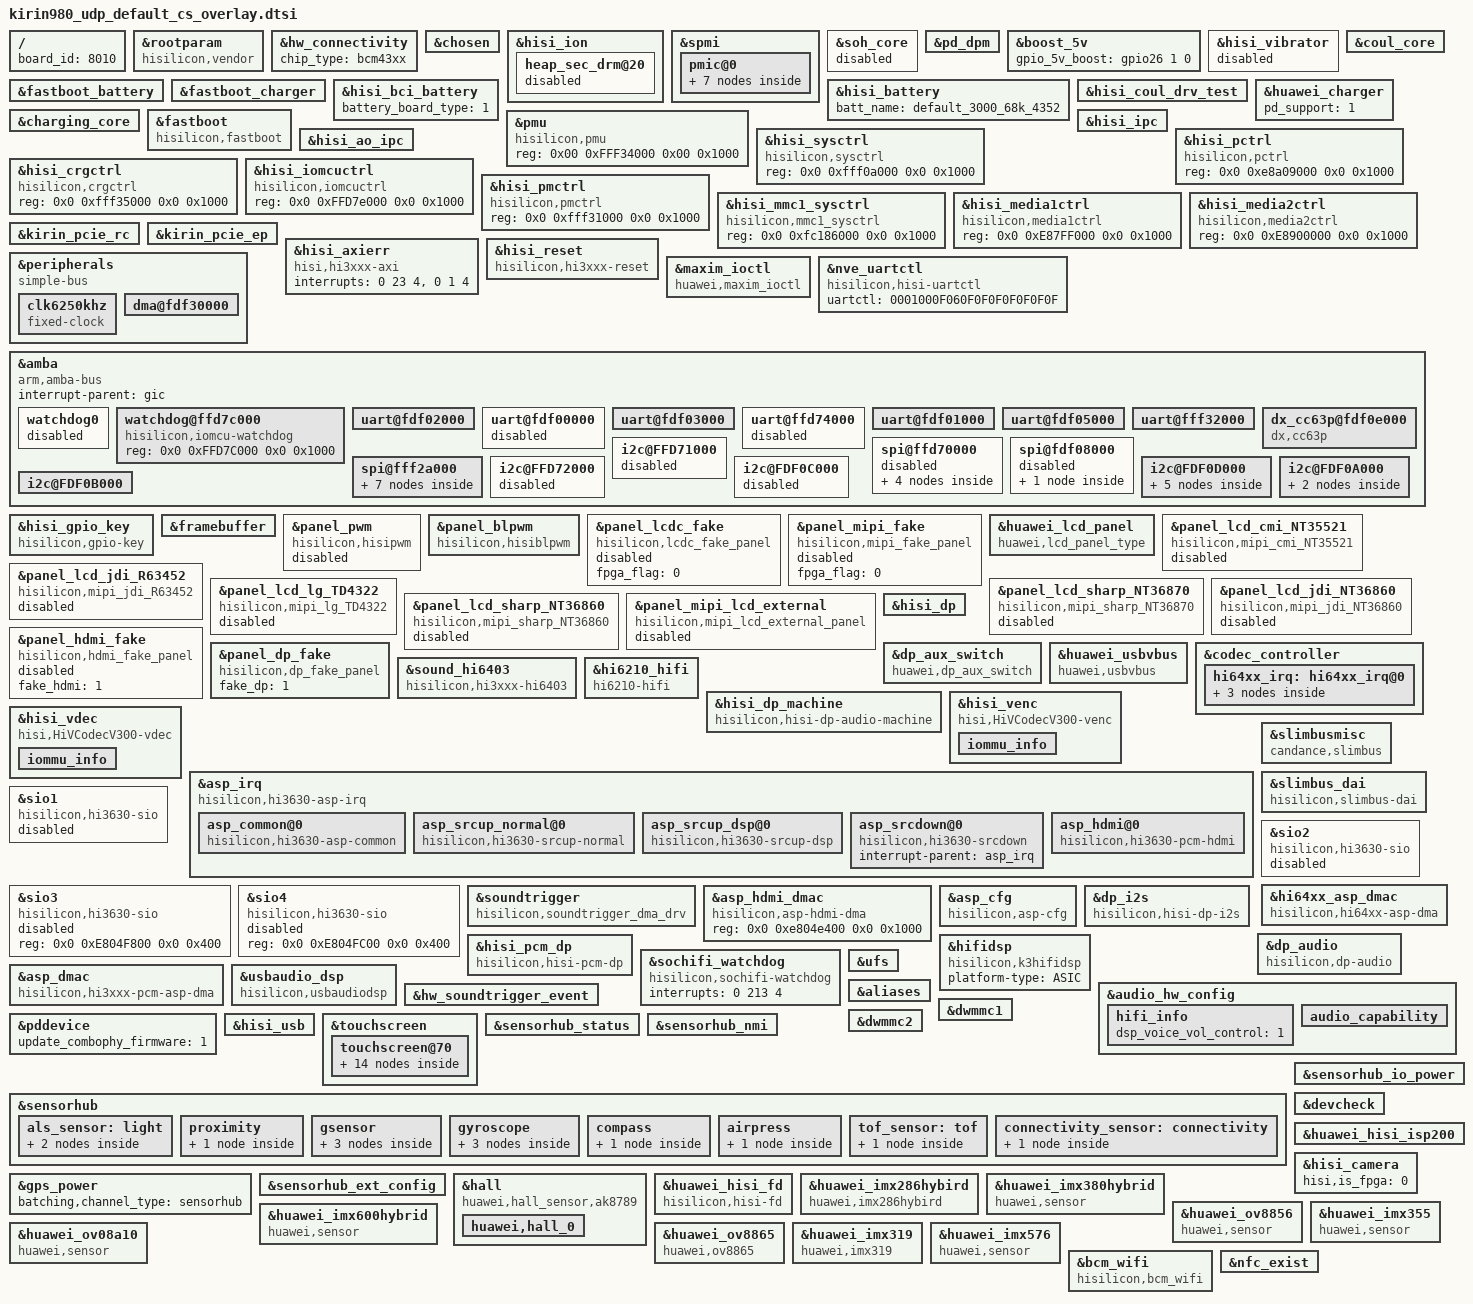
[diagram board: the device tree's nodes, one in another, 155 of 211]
/**
 * Copyright (C) 2014 Hisilicon Ltd.
 *
 *  This program is free software; you can redistribute it and/or modify
 *  it under the terms of the GNU General Public License version 2 as
 *  publishhed by the Free Software Foundation.
 */

/include/ "kirin980_udp_default_cs_pin.dtsi"
/include/ "kirin980_udp_default_cs_modem_pin.dtsi"
/include/ "kirin980_udp_default_cs_hi6402_pin.dtsi"
/include/ "default_3000_68k_4352.dtsi"

/ {
    board_id = <8010>;
};

	&rootparam{
		compatible = "hisilicon,vendor";
		hisi,boardid = <8 0 1 0>;
		hisi,boardname = "kirin980_udp_default_cs";
		hisi,modem_id = <0x37F5FC10>;
		hisi,product_id = <0x37F5FC10>;
	};
	&hw_connectivity {
		/*huawei configuration*/
		chip_type = "bcm43xx";
		status = "ok";
	};
	&chosen {};

	&hisi_ion {
		heap_sec_drm@20 {
			status = "disabled";
		};
	};
	&spmi {
		pmic@0 {
			gpios = <&gpio28 0 0>;
			hisilicon,pmic_fpga_flag=<0>;
				pmic_led@a0 {
					status = "ok";
				};
				pmic_rtc@a0 {
					status = "ok";
				};
				ponkey@b1{
		           		status = "ok";
				};
				pmic_mntn@a0 {
					status = "ok";
				};
				hi6421v700_coul@1 {
					status = "ok";
                                };
				hisi_soh_pmic@1 {
					status = "disabled";
				};
				pmic_vibrator {
					status = "ok";
					hisi_pmic_vibrator,max-timeout-ms = <10000>;
					hisi_pmic_vibrator,label = "vibrator";
					vibrator-reg-on = <0xA000>;
					vibrator-reg-off = <0xA001>;
					vibrator-voltage = <1400>;
					vibrator-boost-power = <0>; // 0: not used 5V, 1 used
					haptics-cfg =
						<0x00 0x00 0x08 0x0f 0x10 0x00 0x18 0x0f 0x1f 0x00 0x26 0x0f 0x2d 0x00 0x32 0x0f 0x37 0x00 0x3b 0x0f 0x3d 0xc0 0x3f 0x0d 0x40 0x00 0x40 0x00 0x40 0x00 0x40 0x00 0x40 0x00 0x40 0x00 0x40 0x00 0x40 0x00>,//6 cycle
						<0x00 0x00 0x08 0x0f 0x10 0x00 0x18 0x0f 0x1f 0x00 0x26 0x0f 0x2d 0x00 0x32 0x0f 0x37 0x00 0x3b 0x0f 0x3d 0x00 0x3f 0x0f 0x40 0x00 0x40 0x0f 0x40 0xf0 0x40 0x07 0x40 0x00 0x40 0x00 0x40 0x00 0x40 0x00>,//8 cycle
						<0x00 0x00 0x08 0x0f 0x10 0x00 0x18 0x0f 0x1f 0x00 0x26 0x0f 0x2d 0x00 0x32 0x0f 0x37 0x00 0x3b 0x0f 0x3d 0x00 0x3f 0x0f 0x40 0x00 0x40 0x0f 0x40 0x00 0x40 0x0f 0x40 0x00 0x40 0x0f 0x40 0xf0 0x40 0x07>,//10 cycle
						<0x00 0x40 0x08 0x0b 0x10 0x40 0x18 0x0b 0x1f 0x40 0x26 0x0b 0x2d 0x40 0x32 0x0b 0x37 0x40 0x3b 0x0b 0x3d 0x50 0x3f 0x0a 0x40 0x00 0x40 0x00 0x40 0x00 0x40 0x00 0x40 0x00 0x40 0x00 0x40 0x00 0x40 0x00>,//%75 6 cycle
						<0x00 0x80 0x08 0x07 0x10 0x80 0x18 0x07 0x1f 0x80 0x26 0x07 0x2d 0x80 0x32 0x07 0x37 0x80 0x3b 0x07 0x3d 0x40 0x3f 0x06 0x40 0x00 0x40 0x00 0x40 0x00 0x40 0x00 0x40 0x00 0x40 0x00 0x40 0x00 0x40 0x00>;//%50 6 cycle
				};
		};
	};
	&soh_core {
		status = "disabled";
	};
	&pd_dpm {
		uart_use_sbu = <1>;
		uart_rx_gpio = <&gpio4 5 0>;
		uart_tx_gpio = <&gpio4 6 0>;
		status = "ok";
	};

	&boost_5v {
		gpio_5v_boost = <&gpio26 1 0>;
		status = "ok";
	};

	&hisi_vibrator {
		status = "disabled";
	};

	&fastboot_battery {
		status = "ok";
	};
	&fastboot_charger {
		hw_charger_type = <4>;
		chip_i2c_num = <6>;
		status = "ok";
	};
	&hisi_battery {
		batt_name = <&default_3000_68k_4352>;
		status = "ok";
	};
	&hisi_bci_battery {
		battery_board_type = <1>; /*0:sft 1:udp 2:asic*/
		status = "ok";
	};
	&coul_core {
		adc_batt_id = <11>;
		adc_batt_temp = <10>;
		r_coul_mohm = <5>;
		status = "ok";
	};
	&hisi_coul_drv_test {
		status = "ok";
	};
	&huawei_charger {
		pd_support = <1>;
		status = "ok";
	};
	&charging_core {
		status = "ok";
	};

	&fastboot {
		compatible = "hisilicon,fastboot";
		i2c3-pin = <0>;
		gpio-keyup = <213>;
		gpio-keydown = <210>;
		uart-board-type = <1>;
		/*UDP_TYPE 0,PRODUCT 1,FPGA 2,EMU 3*/
		lpm3-board-type = <0>;
		jtagtosd-board-type = <2>;
		motor-vib_type = <0>;

		i2c-select = <1>;
		i2c-sel0-gpio = <164>;
		i2c-sel1-gpio = <165>;
		i2c-sel0-val = <0>;
		i2c-sel1-val = <0>;
	};

	&pmu {
		compatible = "hisilicon,pmu";
		reg = <0x00 0xFFF34000 0x00 0x1000>;
		status = "ok";
	};

	&hisi_ipc {

	};
	&hisi_ao_ipc {

	};

        &hisi_sysctrl {
                compatible = "hisilicon,sysctrl";
                reg = <0x0 0xfff0a000 0x0 0x1000>;
                status = "ok";
        };

        &hisi_pctrl {
                compatible = "hisilicon,pctrl";
                reg = <0x0 0xe8a09000 0x0 0x1000>;
                status = "ok";
        };

        &hisi_crgctrl {
                compatible = "hisilicon,crgctrl";
                reg = <0x0 0xfff35000 0x0 0x1000>;
                status = "ok";
        };

	&hisi_iomcuctrl {
                compatible = "hisilicon,iomcuctrl";
                reg = <0x0 0xFFD7e000 0x0 0x1000>;
                status = "ok";
        };

        &hisi_pmctrl {
                compatible = "hisilicon,pmctrl";
                reg = <0x0 0xfff31000 0x0 0x1000>;
                status = "ok";
        };

        &hisi_mmc1_sysctrl {
                compatible = "hisilicon,mmc1_sysctrl";
                reg = <0x0 0xfc186000 0x0 0x1000>;
                status = "ok";
        };

        &hisi_media1ctrl {
                compatible = "hisilicon,media1ctrl";
                reg = <0x0 0xE87FF000 0x0 0x1000>;
                status = "ok";
        };

        &hisi_media2ctrl {
                compatible = "hisilicon,media2ctrl";
                reg = <0x0 0xE8900000 0x0 0x1000>;
                status = "ok";
        };
	&kirin_pcie_rc {
		/* WL_EN GPIO, for Hardware and SoC dependability test */
		wl_power = <200>;

		/* LTR latency param comes from EP: BCM43596 -- 0x10031003 */
		ep_ltr_latency = <0x10031003>;

		/* T-poweron comes from EP: BCM43596 -- 0x10031003 */
		ep_l1ss_ctrl2 = <0x61>;

		/* the lower_16(l1ss_ctrl1) 0x370F needed by RC and must be set; the upper_16 comes from EP*/
		l1ss_ctrl1 = <0x4004370F>;

		/* Delay time come from BCM43596 powerup sequence */
		t_ref2perst = <21000 23000>;
		t_perst2access = <7000 8000>;
		t_perst2rst = <10000 11000>;
	};


	&kirin_pcie_ep {
	};

	&hisi_axierr {
	        compatible = "hisi,hi3xxx-axi";
	        interrupts = <0 23 4>, <0 1 4>;
	        status = "ok";
        };

    &hisi_reset {
            compatible = "hisilicon,hi3xxx-reset";
            status = "ok";
        };

	&peripherals {
		compatible = "simple-bus";
		#address-cells = <1>;
		#size-cells = <1>;
		ranges = <0x0 0x00000000 0x0 0xffffffff>;

		clk6250khz {
			compatible = "fixed-clock";
			#clock-cells = <0>;
			clock-frequency = <6297600>;
			clock-output-names = "clk6250khz";
		};
/*
		clk4800khz {
			compatible = "fixed-clock";
			#clock-cells = <0>;
			clock-frequency = <32768>;
			clock-output-names = "clk4800khz";
		};
*/

		dma@fdf30000 {
			status = "ok";
		};
	};

	&maxim_ioctl {
		compatible = "huawei,maxim_ioctl";
		status = "ok";
	};

	&nve_uartctl {
		compatible = "hisilicon,hisi-uartctl";
		uartctl = "0001000F060F0F0F0F0F0F0F";
	};
	&amba {
		#address-cells = <2>;
		#size-cells = <2>;
		compatible = "arm,amba-bus";
		interrupt-parent = <&gic>;
		ranges;

		/*rtc0: rtc@FFF04000 {
				compatible = "arm,rtc-pl031", "arm,primecell";
				reg = <0xfff04000 0x1000>;
				interrupts = <0 46 0x4>;
				clocks = <&pclk>;
				clock-names = "apb_pclk";
				status = "ok";
		};*/

		/* rtc@FFF05000 {
				compatible = "arm,rtc-pl031", "arm,primecell";
				reg = <0xfff05000 0x1000>;
				interrupts = <0 47 0x4>;
				clocks = <&pclk>;
				clock-names = "apb_pclk";
				status = "ok";
		};*/

		watchdog0 {
			status = "disabled";
		};

                watchdog@ffd7c000{
                        compatible = "hisilicon,iomcu-watchdog";
                        reg = <0x0 0xFFD7C000 0x0 0x1000>;
                        status = "ok";
                };

		/*wdt1@e8a07000 {
			compatible = "arm,sp805", "arm,primecell";
			reg = <0x0 0xe8a07000 0x0 0x1000>;
			interrupts = <0 45 4>;
			clocks = <&pclk_gate_wd0 &pclk>;
			clock-names = "pclk_wd0", "apb_pclk";
		};*/

		uart@fdf02000 {
			status = "ok";
		};

		uart@fdf00000 {
			status = "disabled";
		};

		uart@fdf03000 {
			status = "ok";
		};

		uart@ffd74000 {
			status = "disabled";
		};

		uart@fdf01000 {
			status = "ok";
		};

		uart@fdf05000 {
			status = "ok";
		};

		uart@fff32000 {
			status = "ok";
		};

		dx_cc63p@fdf0e000 {
			compatible = "dx,cc63p";
			reg = <0x0 0xfdf0e000 0x0 0x1000>;
			interrupt-parent = <&gic>;
			interrupts = <0 135 4>;
			status = "ok";
		};

		spi@ffd70000 {
			status = "disabled";
			spi_dev0@0 {
					compatible = "spi_dev0";
					spi-max-frequency = <100000>;
					reg = <0>;
					pl022,com-mode = <0>;
					pl022,interface = <0>;
					pl022,rx-level-trig = <3>;
					pl022,tx-level-trig = <3>;
					pl022,ctrl-len = <7>;
					pl022,wait-state = <0>;
					pl022,duplex = <0>;
					pl022,slave-tx-disable = <0>;
			};

			spi_dev1@1 {
					compatible = "spi_dev1";
					spi-max-frequency = <13000000>;
					reg = <1>;
					pl022,com-mode = <1>;
					pl022,interface = <0>;
					pl022,rx-level-trig = <3>;
					pl022,tx-level-trig = <3>;
					pl022,ctrl-len = <7>;
					pl022,wait-state = <0>;
					pl022,duplex = <0>;
					pl022,slave-tx-disable = <0>;
			};

			spi_dev2@2 {
					compatible = "spi_dev2";
					spi-max-frequency = <13000000>;
					reg = <2>;
					pl022,com-mode = <2>;
					pl022,interface = <0>;
					pl022,rx-level-trig = <3>;
					pl022,tx-level-trig = <3>;
					pl022,ctrl-len = <7>;
					pl022,wait-state = <0>;
					pl022,duplex = <0>;
					pl022,slave-tx-disable = <0>;
			};

			spi_dev3@3 {
					compatible = "spi_dev3";
					spi-max-frequency = <13000000>;
					reg = <3>;
					pl022,com-mode = <0>;
					pl022,interface = <0>;
					pl022,rx-level-trig = <3>;
					pl022,tx-level-trig = <3>;
					pl022,ctrl-len = <7>;
					pl022,wait-state = <0>;
					pl022,duplex = <0>;
					pl022,slave-tx-disable = <0>;
			};
		};

		spi@fdf08000 {
			status = "disabled";
			spi_dev10@10 {
					compatible = "spi_dev10";
					spi-max-frequency = <100000>;
					reg = <0>;
					pl022,com-mode = <0>;
					pl022,interface = <0>;
					pl022,rx-level-trig = <3>;
					pl022,tx-level-trig = <3>;
					pl022,ctrl-len = <7>;
					pl022,wait-state = <0>;
					pl022,duplex = <0>;
					pl022,slave-tx-disable = <0>;
			};
		};

		spi@fff2a000 {
			status = "ok";
			huawei_thp@10 {
				compatible = "huawei,thp";
				spi-max-frequency = <10000000>;
				spi-bus-id = <3>;
				reg = <0>;
				kirin-udp;
				pl022,com-mode = <2>;
				pl022,interface = <0>;
				pl022,rx-level-trig = <3>;
				pl022,tx-level-trig = <3>;
				pl022,ctrl-len = <7>;
				pl022,wait-state = <0>;
				pl022,duplex = <0>;
				pl022,slave-tx-disable = <0>;
				irq_gpio = <&gpio26 4 0>;
				cs_gpio = <&gpio29 4 0>;
				rst_gpio = <&gpio1 7 0>;
				boot_reset_hi_delay_ms = <1>;
				boot_reset_low_delay_ms = <0>;
				boot_reset_after_delay_ms = <0>;
				resume_reset_after_delay_ms = <1>;
				suspend_reset_after_delay_ms = <0>;
				spi_sync_cs_hi_delay_ns = <200>;
				spi_sync_cs_low_delay_ns = <10>;
				thp_input_dev {
					compatible = "huawei,thp_input";
					abs_max_x = <1440>;
					abs_max_y = <2560>;
				};
				novatech {
					spi_sync_cs_hi_delay_ns = <200>;
					spi_sync_cs_low_delay_ns = <200>;
				};
				rohm-bu21150 {
					spi_sync_cs_hi_delay_ns = <200>;
					spi_sync_cs_low_delay_ns = <10>;
				};
			};

			spi_dev30@30 {
					compatible = "spi_dev30";
					spi-max-frequency = <13000000>;
					reg = <1>;
					pl022,com-mode = <0>;
					pl022,interface = <0>;
					pl022,rx-level-trig = <3>;
					pl022,tx-level-trig = <3>;
					pl022,ctrl-len = <7>;
					pl022,wait-state = <0>;
					pl022,duplex = <0>;
					pl022,slave-tx-disable = <0>;
			};

			spi_dev31@31 {
					compatible = "spi_dev31";
					spi-max-frequency = <13000000>;
					reg = <2>;
					pl022,com-mode = <1>;
					pl022,interface = <0>;
					pl022,rx-level-trig = <3>;
					pl022,tx-level-trig = <3>;
					pl022,ctrl-len = <7>;
					pl022,wait-state = <0>;
					pl022,duplex = <0>;
					pl022,slave-tx-disable = <0>;
			};

			spi_dev32@32 {
					compatible = "spi_dev32";
					spi-max-frequency = <13000000>;
					reg = <3>;
					pl022,com-mode = <2>;
					pl022,interface = <0>;
					pl022,rx-level-trig = <3>;
					pl022,tx-level-trig = <3>;
					pl022,ctrl-len = <7>;
					pl022,wait-state = <0>;
					pl022,duplex = <0>;
					pl022,slave-tx-disable = <0>;
			};

		};
		/* I2C0 ~ I2C4 */
		i2c@FFD71000 {
			status = "disabled";
		};

		i2c@FFD72000 {
			status = "disabled";
		};

		i2c@FDF0C000 {
			status = "disabled";
		};

		i2c@FDF0D000 {
			status = "ok";

			smartpa@31 {
				status = "ok";
				gain_incall = <0x16>;
				gain = <0x16>;
			};

			smartpa@34 {
				status = "ok";
				gain_incall = <0x16>;
				gain = <0x16>;
			};

			hisi,ncp6925@50{
				compatible = "hisi,ncp6925";
				reg = <0x50>;
				hisi,pmic_name = "ncp6925";
				hisi,pmic_index = <0>;
				hisi,slave_address = <0x50>;
				hisi,pmic-pin = <75 999 999>;
				hisi,pmic-voltage = <0x0 0x1 0x2 0x3 0x4 0x5 0x6>;
				hisi,pmic_ex_func_disable = <1>;
				status = "ok";
			};
            huawei,lm3646@67{
                compatible = "huawei,lm3646";
                reg = <0x67>;
                huawei,flash-name = "lm3646";
                huawei,flash-index = <0>;
                huawei,flash-type = <0>;
                huawei,slave-address = <0x67>;
                huawei,flash-ctrltype = <1>;
                huawei,need-wakelock = <0>;
                huawei,flash-chipid = <0x11>;
                huawei,flash_led_num = <336>;
                huawei,flash_led = <0x0 0x1 0x2 0x3 0x4 0x5 0x6 0x7 0x8 0x9 0xa>;
				huawei,flash-pin = <231 999 999>;
                huawei,torch_led_num = <336>;
                huawei,torch_led = <0x0 0x1 0x2 0x3 0x4 0x5 0x6 0x7>;
                huawei,led-type = <1>; /* 1, dual tempature; 0, dual white */
                huawei,flash-current = <0x7c 0x7f 0x0>;
                status = "ok";
            };

			nfc@28{
				status = "ok";
				reg = <0x28>;
				compatible = "hisilicon,pn547_nfc";
				nfc_on_type = "hi6421v700_pmic";
				nfc_brcm_conf_name = "libnfc-brcm.conf";
				nfc_nxp_name = "libnfc-nxp.conf";
				nfc_card_num = <0x2>;
				clk_status ="pmu_hi6421v700";
				pn547,dload = <&gpio31 2 0>;
				pn547,irq = <&gpio27 3 0>;
				pn547,ven = <>;
				pinctrl-1 = <&gpio250_pmx_idle &gpio219_pmx_idle>;
				pinctrl-0 = <&gpio250_pmx_func &gpio219_pmx_func>;
				pinctrl-names = "default","idle";
				clock-names = "clk_out0";
				clocks = <&clk_gate_out0>;
				nfc_chip_type = "pn553";
				nfc_single_channel = "true";
				nfc_ese_type = "hisee";
			};

		};

		i2c@FDF0A000 {
			status = "ok";

			hi6523_charger_i2c6@6B{
				status = "ok";
				gpio_int = <&gpio27 2 0>;
			};
			rt1711_kirin980_i2c6@4e {
				status = "ok";
				rt1711,irq_pin = <&gpio25 7 0>;
			};
		};

		i2c@FDF0B000 {
			status = "ok";
		};
	};
	/* end amba */

	&hisi_gpio_key {
		compatible = "hisilicon,gpio-key";
		pinctrl-names = "default", "idle";
		pinctrl-0 = <&gpio213_cfg_func &gpio210_cfg_func>;
		pinctrl-1 = <&gpio213_cfg_idle &gpio210_cfg_idle>;
		gpio-keyup,gpio-irq = <&gpio26 5 0>;
		gpio-keydown,gpio-irq = <&gpio26 2 0>;
		status = "ok";
	};

	/* display start */
	&framebuffer {
		fpga_flag = <0>;
		//FB_ACCEL_KIRIN980
		dss_version_tag = <0x100>;
	};

	&panel_pwm {
		#address-cells = <2>;
		#size-cells = <2>;
		compatible = "hisilicon,hisipwm";
		reg = <0 0xE8A04000 0 0x1000>;
		clocks = <&clk_gate_pwm>;
		clock-names = "clk_pwm";
		//pinctrl-names = "default","idle";
		//pinctrl-0 = <&gpio182_pmx_func &gpio182_cfg_func>;
		//pinctrl-1 = <&gpio182_pmx_idle &gpio182_cfg_idle>;
		fpga_flag = <0>;
		status = "disabled";
	};

	&panel_blpwm {
		#address-cells = <2>;
		#size-cells = <2>;
		compatible = "hisilicon,hisiblpwm";
		reg = <0 0xFFD75000 0 0x1000>;
		clocks = <&clk_gate_blpwm>;
		clock-names = "clk_blpwm";
		pinctrl-names = "default","idle";
		pinctrl-0 = <&gpio185_pmx_func &gpio186_pmx_func &gpio185_cfg_func &gpio186_cfg_func>;
		pinctrl-1 = <&gpio185_pmx_idle &gpio186_pmx_idle &gpio185_cfg_idle &gpio186_cfg_idle>;
		fpga_flag = <0>;
		status = "ok";
	};

	&panel_lcdc_fake {
		#address-cells = <2>;
		#size-cells = <2>;
		compatible = "hisilicon,lcdc_fake_panel";
		fpga_flag = <0>;
		status = "disabled";
	};

	&panel_mipi_fake {
		#address-cells = <2>;
		#size-cells = <2>;
		compatible = "hisilicon,mipi_fake_panel";
		fpga_flag = <0>;
		status = "disabled";
	};

	&huawei_lcd_panel {
		compatible = "huawei,lcd_panel_type";
		detect_type = <0>;		/*0:DETECT_GPIOID  1:DETECT_CHIPID  2:DETECT_LCD_TYPE */
		gpio_id = <16 9>;
		gpio_cfg_addr = <0xE896CF24 0xE896CF08>;
		support_lcd_type = "JDI_R63452_LCD", "LG_TD4322_LCD", "SHARP_NT36870_LCD";
		lcd_id_match_tab = <0 4 2>;
	};

	&panel_lcd_cmi_NT35521 {
		#address-cells = <2>;
		#size-cells = <2>;
		compatible = "hisilicon,mipi_cmi_NT35521";
		//2:PWM,  4:BLPWM,  8:MIPI
		lcd-bl-type = <8>;
		//8:PANEL_MIPI_VIDEO,  16:PANEL_MIPI_CMD
		lcd-display-type = <8>;
		//0:IFBC_TYPE_NONE
		lcd-ifbc-type = <0>;
		//gpio_lcd_vcc1v8, gpio_lcd_p5v5_enable, gpio_lcd_n5v5_enable, gpio_lcd_reset, gpio_lcd_bl_enable
		gpios = <&gpio16 2 0>, <&gpio16 0 0>,  <&gpio20 7 0>, <&gpio17 3 0>, <&gpio20 6 0>;
		gpio_nums = <130 128 167 139 166>;
		//lcdio-vcc-supply = <&ldo4>;
		//lcdanalog-vcc-supply = <&ldo17>;
		//pinctrl-names = "default", "idle";
		//pinctrl-0 = <&gpio021_pmx_func &gpio021_cfg_func &gpio009_cfg_func &gpio010_cfg_func &gpio015_cfg_func &gpio020_cfg_func>;
		//pinctrl-1 = <&gpio021_pmx_idle &gpio021_cfg_idle &gpio009_cfg_idle &gpio010_cfg_idle &gpio015_cfg_idle &gpio020_cfg_idle>;
		fpga_flag = <1>;
		status = "disabled";
	};

	&panel_lcd_jdi_R63452 {
		#address-cells = <2>;
		#size-cells = <2>;
		compatible = "hisilicon,mipi_jdi_R63452";
		//2:PWM,  4:BLPWM,  8:MIPI
		lcd-bl-type = <4>;
		//8:PANEL_MIPI_VIDEO,  16:PANEL_MIPI_CMD ,32:PANEL_DUAL_MIPI_VIDEO, 64:PANEL_DUAL_MIPI_CMD
		lcd-display-type = <16>;
		//0:IFBC_TYPE_NONE 7:IFBC_TYPE_VESA3X_SINGLE 9:IFBC_TYPE_VESA3X_DUAL
		lcd-ifbc-type = <0>;
		//vsp, vsn, lcd_reset, bl_enable, ID0,ID1,TE0
		/*vsp, vsn, rst, bl_en, id0, id1, te0*/
		//GPIO_011, GPIO_008, GPIO_189, GPIO_010, GPIO_016, GPIO_009, GPIO_003
		gpios = <&gpio1 3 0>, <&gpio1 0 0>,  <&gpio23 5 0>, <&gpio1 2 0>, <&gpio2 0 0>, <&gpio1 1 0>, <&gpio0 3 0>;
		gpio_nums = <11 8 189 10 16 9 3>;
		lcdio-vcc-supply = <&ldo4>;
		lcdanalog-vcc-supply = <&ldo17>;
		pinctrl-names = "default", "idle";

		pinctrl-0 = <&gpio011_pmx_func &gpio008_pmx_func &gpio189_pmx_func &gpio010_pmx_func &gpio011_cfg_func &gpio008_cfg_func &gpio189_cfg_func &gpio010_cfg_func &gpio016_cfg_func &gpio009_cfg_func>;
		pinctrl-1 = <&gpio011_pmx_idle &gpio008_pmx_idle &gpio189_pmx_idle &gpio010_pmx_idle &gpio011_cfg_idle &gpio008_cfg_idle &gpio189_cfg_idle &gpio010_cfg_idle &gpio016_cfg_idle &gpio009_cfg_idle>;
		fpga_flag = <0>;
		status = "disabled";
	};
	&panel_lcd_lg_TD4322 {
		compatible = "hisilicon,mipi_lg_TD4322";
		//2:PWM,  4:BLPWM,  8:MIPI
		lcd-bl-type = <4>;
		//8:PANEL_MIPI_VIDEO,  16:PANEL_MIPI_CMD ,32:PANEL_DUAL_MIPI_VIDEO, 64:PANEL_DUAL_MIPI_CMD
		lcd-display-type = <16>;
		//0:IFBC_TYPE_NONE 7:IFBC_TYPE_VESA3X_SINGLE 9:IFBC_TYPE_VESA3X_DUAL
		lcd-ifbc-type = <0>;
		//vsp, vsn, lcd_reset, bl_enable, ID0,ID1,TE0
		/*vsp, vsn, rst, bl_en, id0, id1, te0*/
		//GPIO_011, GPIO_008, GPIO_189, GPIO_010, GPIO_016, GPIO_009, GPIO_003
		gpios = <&gpio1 3 0>, <&gpio1 0 0>,  <&gpio23 5 0>, <&gpio1 2 0>, <&gpio2 0 0>, <&gpio1 1 0>, <&gpio0 3 0>;
		gpio_nums = <11 8 189 10 16 9 3>;
		lcdio-vcc-supply = <&ldo4>;
		lcdanalog-vcc-supply = <&ldo17>;
		pinctrl-names = "default", "idle";

		pinctrl-0 = <&gpio011_pmx_func &gpio008_pmx_func &gpio189_pmx_func &gpio010_pmx_func &gpio011_cfg_func &gpio008_cfg_func &gpio189_cfg_func &gpio010_cfg_func &gpio016_cfg_func &gpio009_cfg_func>;
		pinctrl-1 = <&gpio011_pmx_idle &gpio008_pmx_idle &gpio189_pmx_idle &gpio010_pmx_idle &gpio011_cfg_idle &gpio008_cfg_idle &gpio189_cfg_idle &gpio010_cfg_idle &gpio016_cfg_idle &gpio009_cfg_idle>;
		fpga_flag = <0>;
		status = "disabled";
	};
	&panel_lcd_sharp_NT36870 {
		compatible = "hisilicon,mipi_sharp_NT36870";
		//2:PWM,  4:BLPWM,  8:MIPI
		lcd-bl-type = <4>;
		//8:PANEL_MIPI_VIDEO,  16:PANEL_MIPI_CMD ,32:PANEL_DUAL_MIPI_VIDEO, 64:PANEL_DUAL_MIPI_CMD
		lcd-display-type = <8>;
		//0:IFBC_TYPE_NONE 7:IFBC_TYPE_VESA3X_SINGLE 9:IFBC_TYPE_VESA3X_DUAL
		lcd-ifbc-type = <0>;
		//vsp, vsn, lcd_reset, bl_enable, ID0,ID1,TE0
		/*vsp, vsn, rst, bl_en, id0, id1, te0*/
		//GPIO_011, GPIO_008, GPIO_189, GPIO_010, GPIO_016, GPIO_009, GPIO_003
		gpios = <&gpio1 3 0>, <&gpio1 0 0>,  <&gpio23 5 0>, <&gpio1 2 0>, <&gpio2 0 0>, <&gpio1 1 0>, <&gpio0 3 0>;
		gpio_nums = <11 8 189 10 16 9 3>;
		lcdio-vcc-supply = <&ldo4>;
		lcdanalog-vcc-supply = <&ldo17>;
		pinctrl-names = "default", "idle";

		pinctrl-0 = <&gpio011_pmx_func &gpio008_pmx_func &gpio189_pmx_func &gpio010_pmx_func &gpio011_cfg_func &gpio008_cfg_func &gpio189_cfg_func &gpio010_cfg_func &gpio016_cfg_func &gpio009_cfg_func>;
		pinctrl-1 = <&gpio011_pmx_idle &gpio008_pmx_idle &gpio189_pmx_idle &gpio010_pmx_idle &gpio011_cfg_idle &gpio008_cfg_idle &gpio189_cfg_idle &gpio010_cfg_idle &gpio016_cfg_idle &gpio009_cfg_idle>;
		fpga_flag = <0>;
		status = "disabled";
	};

	&panel_lcd_jdi_NT36860 {
		#address-cells = <2>;
		#size-cells = <2>;
		compatible = "hisilicon,mipi_jdi_NT36860";
		//2:PWM,  4:BLPWM,  8:MIPI
		lcd-bl-type = <8>;
		//8:PANEL_MIPI_VIDEO,  16:PANEL_MIPI_CMD
		lcd-display-type = <16>;
		//0:IFBC_TYPE_NONE 7:IFBC_TYPE_VESA3X_SINGLE 9:IFBC_TYPE_VESA3X_DUAL
		lcd-ifbc-type = <0>;
		//gpio_lcd_vcc1v8, gpio_lcd_p5v5_enable, gpio_lcd_n5v5_enable, gpio_lcd_reset, gpio_lcd_bl_enable, gpio_lcd_tp2v85 ,gpio_lcd_tp1v8
		gpios = <&gpio16 2 0>, <&gpio16 0 0>,  <&gpio20 7 0>, <&gpio17 3 0>, <&gpio20 6 0>, <&gpio17 1 0>, <&gpio16 1 0>;
		gpio_nums = <130 128 167 139 166 137 129>;
		//lcdio-vcc-supply = <&ldo4>;
		//lcdanalog-vcc-supply = <&ldo17>;
		//pinctrl-names = "default", "idle";
		//pinctrl-0 = <&gpio021_pmx_func &gpio021_cfg_func &gpio009_cfg_func &gpio010_cfg_func &gpio015_cfg_func &gpio020_cfg_func>;
		//pinctrl-1 = <&gpio021_pmx_idle &gpio021_cfg_idle &gpio009_cfg_idle &gpio010_cfg_idle &gpio015_cfg_idle &gpio020_cfg_idle>;
		fpga_flag = <0>;
		status = "disabled";
	};

	&panel_lcd_sharp_NT36860 {
		#address-cells = <2>;
		#size-cells = <2>;
		compatible = "hisilicon,mipi_sharp_NT36860";
		//2:PWM,  4:BLPWM,  8:MIPI
		lcd-bl-type = <8>;
		//8:PANEL_MIPI_VIDEO,  16:PANEL_MIPI_CMD
		lcd-display-type = <16>;
		//0:IFBC_TYPE_NONE 7:IFBC_TYPE_VESA3X_SINGLE 9:IFBC_TYPE_VESA3X_DUAL
		lcd-ifbc-type = <0>;
		//gpio_lcd_vcc1v8, gpio_lcd_p5v5_enable, gpio_lcd_n5v5_enable, gpio_lcd_reset, gpio_lcd_bl_enable, gpio_lcd_tp2v85 ,gpio_lcd_tp1v8
		gpios = <&gpio16 2 0>, <&gpio16 0 0>,  <&gpio20 7 0>, <&gpio17 3 0>, <&gpio20 6 0>, <&gpio17 1 0>, <&gpio16 1 0>;
		gpio_nums = <130 128 167 139 166 137 129>;
		//lcdio-vcc-supply = <&ldo4>;
		//lcdanalog-vcc-supply = <&ldo17>;
		//pinctrl-names = "default", "idle";
		//pinctrl-0 = <&gpio021_pmx_func &gpio021_cfg_func &gpio009_cfg_func &gpio010_cfg_func &gpio015_cfg_func &gpio020_cfg_func>;
		//pinctrl-1 = <&gpio021_pmx_idle &gpio021_cfg_idle &gpio009_cfg_idle &gpio010_cfg_idle &gpio015_cfg_idle &gpio020_cfg_idle>;
		fpga_flag = <0>;
		status = "disabled";
	};

	&panel_mipi_lcd_external {
		#address-cells = <2>;
		#size-cells = <2>;
		compatible = "hisilicon,mipi_lcd_external_panel";
		//2:PWM,  4:BLPWM,  8:MIPI
		lcd-bl-type = <8>;
		//8:PANEL_MIPI_VIDEO,  16:PANEL_MIPI_CMD
		lcd-display-type = <8>;
		//0:IFBC_TYPE_NONE
		lcd-ifbc-type = <0>;
		//gpio_lcd_vcc1v8, gpio_lcd_p5v5_enable, gpio_lcd_n5v5_enable, gpio_lcd_reset, gpio_lcd_bl_enable, gpio_TP_2V85_EN_B, gpio_TP_1V8_EN_B
		gpios = <&gpio16 3 0>, <&gpio17 0 0>,  <&gpio20 1 0>, <&gpio17 7 0>, <&gpio20 0 0>, <&gpio17 5 0>, <&gpio16 4 0>;
		gpio_nums = <131 136 161 143 160 141 132>;
		//lcdio-vcc-supply = <&ldo4>;
		//lcdanalog-vcc-supply = <&ldo17>;
		//pinctrl-names = "default", "idle";
		//pinctrl-0 = <&gpio021_pmx_func &gpio021_cfg_func &gpio009_cfg_func &gpio010_cfg_func &gpio015_cfg_func &gpio020_cfg_func>;
		//pinctrl-1 = <&gpio021_pmx_idle &gpio021_cfg_idle &gpio009_cfg_idle &gpio010_cfg_idle &gpio015_cfg_idle &gpio020_cfg_idle>;
		fpga_flag = <0>;
		status = "disabled";
	};
	&panel_hdmi_fake {
		#address-cells = <2>;
		#size-cells = <2>;
		compatible = "hisilicon,hdmi_fake_panel";
		fake_hdmi = <1>;
		status = "disabled";
	};
	&panel_dp_fake {
		#address-cells = <2>;
		#size-cells = <2>;
		compatible = "hisilicon,dp_fake_panel";
		fake_dp = <1>;
		status = "ok";
	};
	&hisi_dp {
		status = "ok";
	};
	&dp_aux_switch {
		compatible = "huawei,dp_aux_switch";
		pinctrl-names = "default", "idle";
		pinctrl-0 = <&gpio137_pmx_func &gpio137_cfg_func>;
		pinctrl-1 = <&gpio137_pmx_idle &gpio137_cfg_idle>;
		cs-gpios = <&gpio17 1 0>;
		status = "ok";
	};

	&huawei_usbvbus {
		compatible = "huawei,usbvbus";
		status = "ok";
	};
	/* display end */

	/* audio device beg */
	&codec_controller {
		gpios = <&gpio26 3 0>; /* GPIO_211 */
		gpio_reset = <74>; /* GPIO_74*/
		gpio_codec_ssi = <204>;
		gpio_codec_ssi_func = <1>;
		gpio_ssi_mux = <16>; /* Chicago only */
		slimbusclk_io_driver = <0x5>;
		slimbusdata_io_driver = <0x5>;
		pm_runtime_support;
		status = "ok";

		hi64xx_irq: hi64xx_irq@0 {
			status = "ok";

			hi6402_codec: hi6402_codec@0{
				hisilicon,mic_num = <2>;
				status = "disabled";
			};

			hi6403_codec: hi6403_codec@0{
				hisilicon,mic_num = <2>;
				status = "ok";
			};

			pmx4: hi6402_pinctrl {
				status = "disabled";
			};
		};
	};

	&sound_hi6403 {
		compatible = "hisilicon,hi3xxx-hi6403";
		status = "ok";
	};

	&hi6210_hifi {
		compatible = "hi6210-hifi";
		status = "ok";
	};

	&hisi_dp_machine {
		compatible = "hisilicon,hisi-dp-audio-machine";
		status = "ok";
	};

  &hisi_venc {
        compatible = "hisi,HiVCodecV300-venc";
        reg = <0x0 0xe8880000 0x0 0x40000>;
        interrupts = <0 296 4>, <0 297 4>, <0 298 4>;
        clocks = <&clk_gate_venc &venc_volt_hold>;
        clock-names = "clk_venc", "venc_volt_hold";
        enc_clk_rate = <600000000>, <480000000>, <277000000>;
        ldo_venc-supply = <&venc>;
        ldo_media-supply = <&venc_fake>;
        venc_qos_mode = <0x1>;
        status = "ok";
        iommu_info {
            start-addr = <0x40000>;
            size = <0xE0000000>;
        };
      };

  &hisi_vdec{
        compatible = "hisi,HiVCodecV300-vdec";
        reg = <0x0 0xe8800000 0x0 0x40000>;
        interrupts = <0 290 4>, <0 291 4>, <0 292 4>;
        clocks = <&clk_gate_vdec>;
        clock-names = "clk_vdec";
        dec_clk_rate = <480000000>, <332000000>, <207500000>;
        ldo_vdec-supply = <&vdec>;
        ldo_media-supply = <&vdec_fake>;
        vdec_qos_mode = <0x1>;
        status = "ok";
        iommu_info {
            start-addr = <0x40000>;
            size = <0xE0000000>;
        };
      };



	&asp_irq {
		compatible = "hisilicon,hi3630-asp-irq";
		reg = <0x0 0xe804e000 0x0 0xa000>;
		#interrupt-cells = <0x2>;
		asp-irq-supply = <&asp>;
		interrupt-controller;
		interrupts = <0x0 0x88 0x4>;
		interrupt-names = "asp_irq";

		asp_common@0 {
			compatible = "hisilicon,hi3630-asp-common";
		};

		asp_srcup_normal@0 {
			compatible = "hisilicon,hi3630-srcup-normal";
			asp-srcup-normal-supply = <&asp>;
			interrupt-parent = <&asp_irq>;
			interrupts = <0x1 0x0>;
			interrupt-names = "asp_srcup_normal";
		};

		asp_srcup_dsp@0 {
			compatible = "hisilicon,hi3630-srcup-dsp";
		};

		asp_srcdown@0 {
			compatible = "hisilicon,hi3630-srcdown";
			interrupt-parent = <&asp_irq>;
		};

		asp_hdmi@0 {
			compatible = "hisilicon,hi3630-pcm-hdmi";
			interrupt-parent = <&asp_irq>;
			interrupts = <0x0 0x0>;
			interrupt-names = "asp_irq_hdmi";
		};
	};
	&slimbusmisc {
		compatible = "candance,slimbus";
		reg = <0x0 0xe8050000 0x0 0xb00>,
			<0x0 0xe804e000 0x0 0xa000>,
			<0x0 0xfff0a000 0x0 0x1000>;
		interrupts = <0x0 0x96 0x4>;
		interrupt-names = "asp_irq_slimbus";
		slimbus-reg-supply = <&asp>;
		pinctrl-names = "default", "idle";
		pinctrl-0 = <&gpio193_pmx_func
				&gpio194_pmx_func
				&gpio193_cfg_func
				&gpio194_cfg_func>;
		pinctrl-1 = <&gpio193_pmx_idle
				&gpio194_pmx_idle
				&gpio193_cfg_idle
				&gpio194_cfg_idle>;
		slimbus-ssi-sel = "slimbus";
		asp_power_state_offset = <0x06c>;
		slimbusclk_io_driver = <0xc8>;
		slimbusdata_io_driver = <0xc3>;
		slimbusclk_offset = <0x034>;
		slimbusdata_offset = <0x038>;
		slimbusclk_cfg_offset = <0x85C>;
		slimbusdata_cfg_offset = <0x860>;
		platform-type   = "UDP";
		codec-type = "slimbus-6403cs";
		clk_asp_subsys = <415000>;
		slimbus_dynamic_freq= "true";
		pm_runtime_support;
		status = "ok";
	};
	&slimbus_dai {
		compatible = "hisilicon,slimbus-dai";
		status = "ok";
	};

	&sio1 {
		compatible = "hisilicon,hi3630-sio";
		reg = <0x0 0xE804F000 0x0 0x400>;
		sio-audio-supply = <&asp>;
		/* wbd
		pinctrl-names = "default", "idle";
		pinctrl-0 = <&gpio183_pmx_func
				    &gpio184_pmx_func
				    &gpio185_pmx_func
				    &gpio186_pmx_func
				    &gpio183_cfg_func
				    &gpio184_cfg_func
				    &gpio185_cfg_func
				     &gpio186_cfg_func>;
		pinctrl-1 = <&gpio183_pmx_idle
				    &gpio184_pmx_idle
				    &gpio185_pmx_idle
				    &gpio186_pmx_idle
				    &gpio183_cfg_idle
				    &gpio184_cfg_idle
				    &gpio185_cfg_idle
				    &gpio186_cfg_idle>;
		*/
		status = "disabled";
	};

	&sio2 {
		compatible = "hisilicon,hi3630-sio";
		reg = <0x0 0xE804F400 0x0 0x400>;
		sio-voice-supply = <&asp>;
		/* wbd
		pinctrl-names = "default", "idle";
		pinctrl-0 = <&gpio043_pmx_func
				     &gpio044_pmx_func
				     &gpio045_pmx_func
				     &gpio046_pmx_func
				     &gpio043_cfg_func
				     &gpio044_cfg_func
				     &gpio045_cfg_func
				     &gpio046_cfg_func>;
			pinctrl-1 = <&gpio043_pmx_idle
				     &gpio044_pmx_idle
				     &gpio045_pmx_idle
				     &gpio046_pmx_idle
				     &gpio043_cfg_idle
				     &gpio044_cfg_idle
				     &gpio045_cfg_idle
				     &gpio046_cfg_idle>;
		*/
		status = "disabled";
	};

	&sio3 {
		compatible = "hisilicon,hi3630-sio";
		reg = <0x0 0xE804F800 0x0 0x400>;
		status = "disabled";
	};

	&sio4 {
		compatible = "hisilicon,hi3630-sio";
		reg = <0x0 0xE804FC00 0x0 0x400>;
		status = "disabled";
	};

	&soundtrigger {
		compatible = "hisilicon,soundtrigger_dma_drv";
		reg = <0x0 0xe804b000 0x0 0x1000>;
		asp-dmac-supply = <&asp>;
		status = "ok";
	};

	&hi64xx_asp_dmac {
		compatible = "hisilicon,hi64xx-asp-dma";
		reg = <0x0 0xe804b000 0x0 0x1000>;
		asp-dmac-supply = <&asp>;
		interrupts = <0 216 4>;
		interrupt-names = "asp_dma_irq";
		status = "ok";
	};

	&asp_hdmi_dmac {
		compatible = "hisilicon,asp-hdmi-dma";
		reg = <0x0 0xe804e400 0x0 0x1000>;
		status = "ok";
	};

	&asp_cfg {
		compatible = "hisilicon,asp-cfg";
		reg = <0x0 0xe804e000 0x0 0xa000>;
		asp-supply = <&asp>;
		status = "ok";
	};

	&dp_i2s {
		compatible = "hisilicon,hisi-dp-i2s";
		status = "ok";
        };

	&dp_audio {
		compatible = "hisilicon,dp-audio";
		status = "ok";
        };

	&hisi_pcm_dp {
		compatible = "hisilicon,hisi-pcm-dp";
		interrupts = <0x0 0x96 0x4>;
		interrupt-names = "asp_hdmi_dma";
		dp-pcm-supply = <&asp>;
		status = "ok";
	};

	&hifidsp {
			compatible = "hisilicon,k3hifidsp";
			status = "ok";
			platform-type = "ASIC";
	};

	&sochifi_watchdog {
		compatible = "hisilicon,sochifi-watchdog";
		interrupts = <0 213 4>;
		status = "ok";
	};

	&asp_dmac {
		compatible = "hisilicon,hi3xxx-pcm-asp-dma";
		reg = <0x0 0xe804b000 0x0 0x1000>;
		asp-dmac-supply = <&asp>;
		status = "ok";
	};

	&usbaudio_dsp {
		compatible = "hisilicon,usbaudiodsp";
		status = "ok";
	};

	&audio_hw_config {
		product_name = "kirin980";
		spk_pa_name = "max98925";
		cust_name = "audio_custom";
		soc_name = "hi363x";
		codec_name = "hi6403";
		codec_dsp_algo = "maxim|mad";
		modem_sio_master = "false";
		ear_pa_name = "max98925";
		pa_alg_bypass = "true";
		status = "ok";

		hifi_info {
			dsp_voice_vol_control = "1";/* 1 :need socdsp control volume; 0:platform codec */
		};

		audio_capability {
			bwe_ui_support = "false";
			bwe_support = "true";
			swb_support = "true";
			wnr_support = "false";
			nv_evs_support = "true";
			lvm_support = "false";
			dhf_support = "false";
			dual_smartpa_support = "true";
			spk_rcv_stereo_support = "true";
			asr_vibrate_support = "true";
		};
	};

	&hw_soundtrigger_event {
		status = "ok";
	};

	/* audio device end */

	/* UFS */
	&ufs {
		status = "ok";
	};

	/* rename eMMC,SD,SDIO */
	&aliases {
	};

	/* eMMC 4.5
	&dwmmc0 {
		status = "ok";
	};
	*/

	/* SD */
	&dwmmc1 {
		status = "ok";
	};

	/* sdio */

	&dwmmc2 {
		status = "ok";
	};

	&pddevice {
		update_combophy_firmware = <1>;
	};

	&hisi_usb {
		host-maximum-speed = "super-speed-plus";
		usb_support_dp = <1>;
		usb_firmware_es = <0>;
		quirk_enable_hst_imm_retry;
		quirk_disable_rx_thres_cfg;
		quirk_disable_usb2phy_suspend;
		quirk_clear_svc_opp_per_hs;
		quirk_set_svc_opp_per_hs_sep;
		quirk_adjust_dtout;
		quirk_force_disable_host_lpm;
		quirk_enable_p4_gate;
	};

	&touchscreen {
		bus_id = <7>;
		status = "ok";
		product = "kirin980_udp";
		has_virtualkey = <0>;
		fpga_flag = <0>;
		touchscreen@70 {
			algo_id = <1>;
			ic_type = <4>;
			projectid_len = <10>;
			vci_gpio_type = <0>;
			vci_regulator_type = <1>;
			vddio_gpio_type = <0>;
			vddio_regulator_type = <1>;
			reset_gpio = <&gpio1 7 0>;
			attn_gpio = <&gpio26 4 0>;
			pinctrl-names = "default", "idle";
			pinctrl-0 = <&gpio212_cfg_func>;
			pinctrl-1 = <&gpio212_cfg_idle>;
			synaptics-vdd-supply = <&ldo17>;
			synaptics-io-supply = <&ldo4>;
			delay_for_fw_update = <1>;
			ghost_detect_support = <1>;
			need_wd_check_status = <1>;
			check_status_watchdog_timeout = <5000>;
			irq_config = <0>;
			flip_x = <1>;
			flip_y = <1>;
			x_max = <1080>;
			y_max = <1920>;
			x_max_mt = <1080>;
			y_max_mt = <1920>;
			raw_data_limit = "4600", /*rawdata-max*/
					 "2300", /*rawdata-min*/
					 "20", /*deltadata-max*/
					 "-20", /*deltadata-min*/
					 "390", /*rx-to-rx-diff-max*/
					 "-390", /*rx-to-rx-diff-min*/
					 "390", /*tx-to-tx-diff-max*/
					 "-390";/*tx-to-tx-diff-min*/
			NEXT11080 {
				compatible = "synaptics-NEXT11080";     //jdi S3320B
				holster_switch_addr = <0x0419>;
				holster_switch_bit = <0>;
				glove_switch_addr = <0x001F>;
				glove_switch_bit = <0>;
				roi_supported = <1>;
				roi_control_addr = <0x041B>;
				roi_control_bit = <0>;
				roi_data_addr = <0x0418>;
			};
			NEXT18100 {
				compatible = "synaptics-NEXT18100";
				ic_type = <3>;
				report_rate_test = <0>;
				supported_func_indicater = <0x01>;
				raw_data_limit = "450", "50", "40", "-40", "390", "-390", "390", "-390";
				holster_switch_addr = <0x001C>;
				holster_switch_bit = <1>;
				glove_switch_addr = <0x001C>;
				glove_switch_bit = <0>;
				roi_supported = <1>;
				roi_control_addr = <0x043A>;
				roi_control_bit = <0>;
				roi_data_addr = <0x0418>;
				};
			MAHA261001 {
				producer = "lg";
				roi_data_addr = <0x0418>;
				roi_control_bit = <0>;
				roi_control_addr = <0x041B>;
				roi_supported = <0>;
				glove_switch_bit = <0>;
				glove_switch_addr = <0x001F>;
				holster_switch_bit = <0>;
				holster_switch_addr = <0x0419>;
				raw_data_limit = "5000", "0", "5000", "-5000", "5000", "-5000", "5000", "-5000";
				report_rate_test = <0>;
				ic_type = <4>;
				rawdata_arrange_type = <1>;
				noise_state_reg = <0x0108>;
				capacitance_test_config = <1>;
				compatible = "synaptics-MAHA261001";
			};
			MAHA211000 {
				roi_data_addr = <0x0418>;
				roi_control_bit = <0>;
				roi_control_addr = <0x041B>;
				roi_supported = <0>;
				glove_switch_bit = <0>;
				glove_switch_addr = <0x001F>;
				holster_switch_bit = <0>;
				holster_switch_addr = <0x0419>;
				ic_type = <4>;
				producer = "lg";
				raw_data_limit = "5000", "0", "5000", "-5000", "5000", "-5000", "5000", "-5000";
				report_rate_test = <0>;
				rawdata_arrange_type = <1>;
				noise_state_reg = <0x0108>;
				capacitance_test_config = <1>;
				compatible = "synaptics-MAHA211000";
			};
			MAHA261601 {
				roi_data_addr = <0x0418>;
				roi_control_bit = <0>;
				roi_control_addr = <0x041B>;
				roi_supported = <0>;
				glove_switch_bit = <0>;
				glove_switch_addr = <0x001F>;
				holster_switch_bit = <0>;
				holster_switch_addr = <0x0419>;
				ic_type = <4>;
				producer = "sharp";
				raw_data_limit = "5000", "0", "5000", "-5000", "5000", "-5000", "5000", "-5000";
				report_rate_test = <0>;
				rawdata_arrange_type = <1>;
				noise_state_reg = <0x0108>;
				capacitance_test_config = <1>;
				compatible = "synaptics-MAHA261601";
			};
			MAHA211600 {
				roi_data_addr = <0x0418>;
				roi_control_bit = <0>;
				roi_control_addr = <0x041B>;
				roi_supported = <0>;
				glove_switch_bit = <0>;
				glove_switch_addr = <0x001F>;
				holster_switch_bit = <0>;
				holster_switch_addr = <0x0419>;
				ic_type = <4>;
				producer = "sharp";
				raw_data_limit = "5000", "0", "5000", "-5000", "5000", "-5000", "5000", "-5000";
				report_rate_test = <0>;
				rawdata_arrange_type = <1>;
				noise_state_reg = <0x0108>;
				capacitance_test_config = <1>;
				compatible = "synaptics-MAHA211600";
			};
			MAHA261011 {
				producer = "lg";
				roi_data_addr = <0x040A>;
				roi_control_bit = <0>;
				roi_control_addr = <0x042D>;
				roi_supported = <1>;
				glove_switch_bit = <5>;
				glove_switch_addr = <0x001B>;
				holster_switch_bit = <1>;
				holster_switch_addr = <0x001D>;
				raw_data_limit = "5000", "0", "5000", "-5000", "5000", "-5000", "5000", "-5000";
				report_rate_test = <0>;
				ic_type = <4>;
				rawdata_arrange_type = <1>;
				noise_state_reg = <0x0108>;
				capacitance_test_config = <1>;
				compatible = "synaptics-MAHA261011";
			};
			MAHA211010 {
				roi_data_addr = <0x0400>;
				roi_control_bit = <0>;
				roi_control_addr = <0x0412>;
				roi_supported = <1>;
				glove_switch_bit = <5>;
				glove_switch_addr = <0x001A>;
				holster_switch_bit = <1>;
				holster_switch_addr = <0x001C>;
				ic_type = <4>;
				producer = "lg";
				raw_data_limit = "2150", "950", "20", "-20", "602", "-602", "602", "-602";
				report_rate_test = <0>;
				rawdata_arrange_type = <1>;
				noise_state_reg = <0x0108>;
				capacitance_test_config = <1>;
				compatible = "synaptics-MAHA211010";
			};
			MAHA261611 {
				roi_data_addr = <0x040A>;
				roi_control_bit = <0>;
				roi_control_addr = <0x042D>;
				roi_supported = <1>;
				glove_switch_bit = <5>;
				glove_switch_addr = <0x001B>;
				holster_switch_bit = <1>;
				holster_switch_addr = <0x001D>;
				ic_type = <4>;
				producer = "sharp";
				raw_data_limit = "5000", "0", "5000", "-5000", "5000", "-5000", "5000", "-5000";
				report_rate_test = <0>;
				rawdata_arrange_type = <1>;
				noise_state_reg = <0x0108>;
				capacitance_test_config = <1>;
				compatible = "synaptics-MAHA261611";
			};
			MAHA211610 {
				roi_data_addr = <0x0400>;
				roi_control_bit = <0>;
				roi_control_addr = <0x0412>;
				roi_supported = <1>;
				glove_switch_bit = <5>;
				glove_switch_addr = <0x001A>;
				holster_switch_bit = <1>;
				holster_switch_addr = <0x001C>;
				ic_type = <4>;
				producer = "sharp";
				raw_data_limit = "2650", "1150", "20", "-20", "1087", "-1087", "1087", "-1087";
				report_rate_test = <0>;
				rawdata_arrange_type = <1>;
				noise_state_reg = <0x0108>;
				capacitance_test_config = <1>;
				compatible = "synaptics-MAHA211610";
			};
			MAHA240800 {
				roi_data_addr = <0x0400>;
				roi_control_bit = <0>;
				roi_control_addr = <0x040D>;
				roi_supported = <1>;
				glove_switch_bit = <0>;
				glove_switch_addr = <0x001D>;
				holster_switch_bit = <1>;
				holster_switch_addr = <0x001D>;
				ic_type = <3>;
				producer = "jdi";
				raw_data_limit = "3000", "1050", "20", "-20", "1506", "-1506", "1506", "-1506";
				report_rate_test = <0>;
				rawdata_arrange_type = <1>;
				noise_state_reg = <0x0108>;
				capacitance_test_config = <1>;
				compatible = "synaptics-MAHA240800";
			};
			MAHA240810 {
				roi_data_addr = <0x0400>;
				roi_control_bit = <0>;
				roi_control_addr = <0x040D>;
				roi_supported = <1>;
				glove_switch_bit = <0>;
				glove_switch_addr = <0x001D>;
				holster_switch_bit = <1>;
				holster_switch_addr = <0x001D>;
				ic_type = <3>;
				producer = "jdi";
				raw_data_limit = "2600", "1000", "25", "-25", "750", "-750", "750", "-750";
				report_rate_test = <0>;
				rawdata_arrange_type = <1>;
				noise_state_reg = <0x0108>;
				capacitance_test_config = <1>;
				compatible = "synaptics-MAHA240810";
			};
			MAHA250801 {
				roi_data_addr = <0x0400>;
				roi_control_bit = <0>;
				roi_control_addr = <0x040D>;
				roi_supported = <1>;
				glove_switch_bit = <0>;
				glove_switch_addr = <0x001D>;
				holster_switch_bit = <1>;
				holster_switch_addr = <0x001D>;
				ic_type = <3>;
				producer = "jdi";
				raw_data_limit = "5000", "0", "5000", "-5000", "5000", "-5000", "5000", "-5000";
				report_rate_test = <0>;
				rawdata_arrange_type = <1>;
				noise_state_reg = <0x0108>;
				capacitance_test_config = <1>;
				compatible = "synaptics-MAHA250801";
			};
			MAHA250811 {
				roi_data_addr = <0x0400>;
				roi_control_bit = <0>;
				roi_control_addr = <0x040D>;
				roi_supported = <1>;
				glove_switch_bit = <0>;
				glove_switch_addr = <0x001D>;
				holster_switch_bit = <1>;
				holster_switch_addr = <0x001D>;
				ic_type = <3>;
				producer = "jdi";
				raw_data_limit = "5000", "0", "5000", "-5000", "5000", "-5000", "5000", "-5000";
				report_rate_test = <0>;
				rawdata_arrange_type = <1>;
				noise_state_reg = <0x0108>;
				capacitance_test_config = <1>;
				compatible = "synaptics-MAHA250811";
			};
		};
	};

	&sensorhub_status{
	};

	&sensorhub_nmi{
	};

	&sensorhub{
		#address-cells=<1>;
		#size-cells=<0>;
		als_sensor:light{
			als1{
				compatible="huawei,rohm_bh1745";
				reg=<0x38>;
				chip_id_value=<0xE0>;
				file_id=<38>;
				sensor_list_info_id = <0x03>;
				poll_interval=<350>;
				gpio_int1=<&gpio26 6 0>;
				als_phone_type = <30>;
				als_phone_version = <12>;
				als_extend_data = <0 0 0 0 0 0 0 0 0 0 0 0>;
				status = "ok";
				sensorlist_name="light-bh1745";
				vendor="rohm";
			};
			als2{
				compatible="huawei,avago_apds9251";
				bus_number = <0x0>;
				reg=<0x52>;
				chip_id_register = <0x06>;
				chip_id_value = <0xB2 0xB5>;
				file_id = <41>;
				sensor_list_info_id = <0x03>;
				sensor_type = "als";
				poll_interval = <350>;
				threshold_value = <0x1>;
				GA1 = <0x1046>;
				GA2 = <0xf3c>;
				GA3 = <0x1194>;
				tp_color = <0x0>;
				again = <0x1>;
				gpio_int1 = <0x38 0x6 0x0>;
				atime = <0xdb>;
				init_time = <0x96>;
				status = "ok";
				als_phone_type = <30>;
				als_phone_version = <12>;
				als_extend_data = <0x0 0x0 0x0 0x0 0x0 0x0 0x0 0x0 0x0 0x0 0x0 0x0>;
				sensorlist_name="als-apds9251";
				vendor="avago";
			};
		};

		proximity{
			ps1{
				compatible="huawei,txc-pa224";
				reg=<0x1e>;
				chip_id_register=<0x7F>;
				chip_id_value=<0x11>;
				file_id=<39>;
				sensor_list_info_id = <0x04>;
				min_proximity_value=<220>;
				pwindows_value=<14>;
				pwave_value=<12>;
				threshold_value=<25>;
				gpio_int1=<&gpio27 1 0>;
				poll_interval = <30>;
				status = "ok";
			};

		};
		gsensor{
			acc1{
				compatible="huawei,st-lsm6ds3";
				bus_number=<0>;
				reg=<0x6a>;
				chip_id_register=<0x0f>;
				chip_id_value=<0x69>;
				file_id=<34>;
				sensor_list_info_id=<0>;
				sensor_type="acc";
				/*sensor-vdd-supply = <&ldo24>;*/
				axis_map_x=<0>;
				axis_map_y=<1>;
				axis_map_z=<2>;
				negate_x=<0>;
				negate_y=<0>;
				negate_z=<0>;
				offset_x=<0>;
				offset_y=<0>;
				offset_z=<0>;
				sensitivity_x=<1>;
				sensitivity_y=<1>;
				sensitivity_z=<1>;
				poll_interval=<10>;
				gpio_int2=<&gpio29 6 0>;
				gpio_int2_sh=<1030>;
				calibrate_style=<0>;
				status = "ok";
			};
			acc2{
				compatible ="huawei,st-lsm6dsm";
				bus_number =<0>;
				reg =<0x6a>;
				chip_id_register =<0x0f>;
				chip_id_value =<0x6a>;
				file_id =<34>;
				sensor_list_info_id =<0>;
				sensor_type ="acc";
				axis_map_x =<0>;
				axis_map_y =<1>;
				axis_map_z =<2>;
				negate_x =<0>;
				negate_y =<0>;
				negate_z =<0>;
				offset_x =<0>;
				offset_y =<0>;
				offset_z =<0>;
				sensitivity_x =<1>;
				sensitivity_y =<1>;
				sensitivity_z =<1>;
				poll_interval =<10>;
				gpio_int2=<&gpio29 6 0>;
				gpio_int2_sh=<1030>;
				calibrate_style =<0>;
				sensorlist_name="accelerometer-lsm6dsm";
				vendor="st";
				status = "ok";
			};
			acc3{
				compatible ="huawei,invensense-icm20690";
				bus_number =<0>;
				reg =<0x68>;
				chip_id_register =<0x75>;
				chip_id_value =<0x20>;
				file_id =<53>;
				sensor_list_info_id =<0>;
				sensor_type ="acc";
				axis_map_x =<0>;
				axis_map_y =<1>;
				axis_map_z =<2>;
				negate_x =<0>;
				negate_y =<0>;
				negate_z =<0>;
				offset_x =<0>;
				offset_y =<0>;
				offset_z =<0>;
				sensitivity_x =<1>;
				sensitivity_y =<1>;
				sensitivity_z =<1>;
				poll_interval =<10>;
				gpio_int2=<&gpio29 6 0>;
				gpio_int2_sh=<1030>;
				calibrate_style =<0>;
				sensorlist_name="accelerometer-icm20690";
				vendor="invensense";
				status = "ok";
			};
		};

		gyroscope{
			gyro1{
				compatible ="huawei,st-lsm6ds3";
				bus_number=<0>;
				reg=<0x6a>;
				chip_id_register=<0x0f>;
				chip_id_value=<0x69>;
				file_id=<36>;
				sensor_list_info_id=<5>;
				sensor_type="gyro";
				/*sensor-vdd-supply = <&ldo24>;*/
				axis_map_x=<1>;
				axis_map_y=<0>;
				axis_map_z=<2>;
				negate_x=<1>;
				negate_y=<1>;
				negate_z=<0>;
				poll_interval=<10>;
				gpio_int2=<&gpio29 6 0>;
				gpio_int2_sh=<1030>;
				sensorlist_name="gyroscope-lsm6ds3";
				vendor="st";
				status = "ok";
			};
			gyro2{
				compatible ="huawei,st-lsm6dsm";
				bus_number =<0>;
				reg =<0x6a>;
				chip_id_register =<0x0f>;
				chip_id_value =<0x6a>;
				file_id =<36>;
				sensor_list_info_id =<5>;
				sensor_type ="gyro";
				axis_map_x =<1>;
				axis_map_y =<0>;
				axis_map_z =<2>;
				negate_x =<1>;
				negate_y =<1>;
				negate_z =<0>;
				poll_interval =<10>;
				gpio_int2=<&gpio29 6 0>;
				gpio_int2_sh=<1030>;
				sensorlist_name="gyroscope-lsm6dsm";
				vendor="st";
				status = "ok";
			};
			gyro3{
				compatible ="huawei,inv-icm20690";
				bus_number =<0>;
				reg =<0x68>;
				chip_id_register =<0x75>;
				chip_id_value =<0x20>;
				file_id =<54>;
				sensor_list_info_id =<5>;
				sensor_type ="gyro";
				axis_map_x =<1>;
				axis_map_y =<0>;
				axis_map_z =<2>;
				negate_x =<1>;
				negate_y =<1>;
				negate_z =<0>;
				poll_interval =<10>;
				gpio_int2=<&gpio29 6 0>;
				gpio_int2_sh=<1030>;
				sensorlist_name="gyroscope-icm20690";
				vendor="invensense";
				status = "ok";
			};
		};
		compass{
			mag1{
				compatible="huawei,akm-akm09911";
				bus_number=<0>;
				reg=<0x0D>;
				chip_id_register=<0x00>;
				chip_id_value=<0x48>;
				file_id=<37>;
				sensor_list_info_id=<1>;
				sensor_type="mag";
				/*sensor-vdd-supply = <&ldo24>;*/
				outbit=<0>;
				calibrate_method=<2>;
				axis_map_x=<1>;
				axis_map_y=<0>;
				axis_map_z=<2>;
				negate_x=<1>;
				negate_y=<0>;
				negate_z=<0>;
				poll_interval=<10>;
				gpio_int1=<&gpio0 0 0>;
				gpio_reset=<&gpio0 0 0>;
				softiron_parameter = <13 39 19 255 59 00 19 255 59 41 221 255 59 00 221 255 102 42 0 0 0 0 0 0 0 0 0>;
				status = "ok";
			};
		};
		airpress{
			airpress1{
				compatible="huawei,st_lps22bh";
				bus_number=<0>;
				reg=<0x5d>;
				chip_id_register=<0x0F>;
				chip_id_value=<0xB1>;
				file_id=<48>;
				sensor_list_info_id=<0x9>;
				sensor_type="airpress";
				poll_interval = <500>;
				sensorlist_name="airpress-lps22bh";
				vendor="st";
				status = "ok";
			};
		};
        tof_sensor:tof{
            tof1{
                compatible="huawei,ams_tmf8701";
                bus_number=<0>;
                reg=<0x41>;
                chip_id_register=<0xe3>;
                chip_id_value=<0x07>;
                file_id=<99>;
                sensor_list_info_id=<0x9>;
                sensor_type="tof";
                poll_interval = <500>;
                sensorlist_name="ams-tmf8701";
                vendor="ams";
                status = "ok";
            };
        };
		connectivity_sensor:connectivity{
			connectivity1{
				compatible="huawei,connectivity-vs";
				bus_type = <145>;
				bus_number = <1>;
				i2c_address = <0x6e>;
				reg=<0x6e>;
				chip_id_register=<0x91>;
				chip_id_value=<0x00>;
				file_id=<47>;
				sensor_list_info_id=<0x23>;
				sensor_type="connectivity";
				gpio1_gps_cmd_ap = <227>;
				gpio1_gps_cmd_sh = <1027>;
				gpio2_gps_ready_ap = <198>;
				gpio2_gps_ready_sh = <1005>;
				gpio3_wakeup_gps_ap = <199>;
				gpio3_wakeup_gps_sh = <1006>;
				status = "ok";
			};
		};
	};

	&gps_power {
		status = "ok";
		batching,channel_type = "sensorhub";
	};

	&sensorhub_ext_config {
		adapt_sensor_list_id = <0x2 0x6 0x7 0x8 0x9 0x11 0x1a 0x1b 0x1c 0x22>;
		adapt_file_id = <14>;
	};

	&sensorhub_io_power{
	};

	&hall {
		compatible = "huawei,hall_sensor,ak8789";
		status = "ok";
		huawei,hall_0{
			huawei,single-n-pole = <&gpio23 1 0>;
			huawei,type = <0x01>;
			huawei,default-state = "on";
		};
	};
	/*
		device check : the 0 means that it don't need to check;
			the 1 means that it check at board check and running test;
			the 2 means that it check at running test
	*/
	&devcheck {
		touch_panel = <2>;
		compass = <1>;
		g_sensor = <1>;
		gyroscope = <1>;
		nfc = <1>;
		dc_dc = <1>;
		tps = <1>;
		l_sensor = <2>;
		charge = <1>;
		usb_switch = <1>;
		wifi = <1>;
		bt = <1>;
		gps = <1>;
		antenna_ctl = <0>;
		airpress = <1>;
		vibrator_lra = <1>;
		status = "ok";
	};

	&huawei_hisi_isp200 {
		hisi,is_fpga = <0>;
	pinctrl-names = "default", "idle";
	pinctrl-0 = <
		&gpio020_pmx_func
		&gpio021_pmx_func
		&gpio022_pmx_func
		&gpio023_pmx_func
		&gpio024_pmx_func
		&gpio025_pmx_func
		&gpio026_pmx_func
		&gpio027_pmx_func
		&gpio028_pmx_func
		&gpio230_pmx_func
		&gpio012_pmx_func
		&gpio007_pmx_func

		&gpio020_cfg_func
		&gpio021_cfg_func
		&gpio022_cfg_func
		&gpio023_cfg_func
		&gpio024_cfg_func
		&gpio025_cfg_func
		&gpio026_cfg_func
		&gpio027_cfg_func
		&gpio028_cfg_func
		&gpio230_cfg_func
		&gpio012_cfg_func
		&gpio007_cfg_func
		>;
	pinctrl-1 = <
		&gpio020_pmx_idle
		&gpio021_pmx_idle
		&gpio022_pmx_idle
		&gpio023_pmx_idle
		&gpio024_pmx_idle
		&gpio025_pmx_idle
		&gpio026_pmx_idle
		&gpio027_pmx_idle
		&gpio028_pmx_idle
		&gpio230_pmx_idle
		&gpio012_pmx_idle
		&gpio007_pmx_idle

		&gpio020_cfg_idle
		&gpio021_cfg_idle
		&gpio022_cfg_idle
		&gpio023_cfg_idle
		&gpio024_cfg_idle
		&gpio025_cfg_idle
		&gpio026_cfg_idle
		&gpio027_cfg_idle
		&gpio028_cfg_idle
		&gpio230_cfg_idle
		&gpio012_cfg_idle
		&gpio007_cfg_idle
		>;
	status = "ok";
	};

	&hisi_camera {
		hisi,is_fpga = <0>;
	};

	&huawei_hisi_fd {
		compatible = "hisilicon,hisi-fd";
		reg = <0x0 0xE8340000 0x0 0x20000>,    //FD reg
		      <0x0 0xE8320000 0x0 0x20000>,    //smmu reg
		      <0x0 0xE8303000 0x0 0x1000>;     //smmu master reg
		      huawei,top-base = <0xE8304000 0x1000>;
		hisi-fd-supply = <&ispsubsys>;
		hisi-media-supply = <&media1_subsys>;
		clocks = <&clk_gate_fd_func &clk_gate_jpg_func>;
		clock-names = "clk_fd_func", "clk_jpg_func";
		clock-value = <384000000>;
		clock-low-frequency = <277000000>;
		interrupts = <0 307 4>;
		huawei,smmu-flag = <1>;
		huawei,ram-config = <1>;
		smmu_offset_list = <0x10 0x1c 0x20 0x204 0x20c 0x220 0x224>;
		mstr_offset_list = <0x28 0x34 0x100 0x260 0x3c0>;
		fd_offset_list = <0x418 0x40c 0x410 0x414 0x464 0xFD 0x7A 0x9F 0x58 0x31c 0x470>;
		status = "ok";
	};

	&huawei_imx286hybird {
		compatible = "huawei,imx286hybird";
		huawei,sensor_name = "IMX286HYBIRD";
		huawei,sensor_index = <0>;
		huawei,is_fpga = <0>;
		huawei,pd_valid = <1>;
		huawei,reset_valid = <1>;
		huawei,vcmpd_valid = <0>;
		huawei,csi_index = <0 2>;
		huawei,i2c_index = <0 2>;
		/*
		phy clk define before snclk & the num of phy clk is equal to phy-clock-num
		*/
		clocks = <&clk_gate_rxdphy0_cfg &clk_gate_rxdphy1_cfg &clk_gate_rxdphy2_cfg &clk_gate_rxdphy3_cfg &clk_gate_isp_snclk0 &clk_gate_isp_snclk2>;
		clock-names = "clk_rxdphy0_cfg", "clk_rxdphy1_cfg", "clk_rxdphy2_cfg", "clk_rxdphy3_cfg", "clk_isp_snclk0", "clk_isp_snclk2";
		huawei,mclk = <24000000>;
		huawei,phyclk = <80000000>;
		phy-clock-num = <4>;
		dvdd-supply = <&ldo32>;
		iovdd-supply = <&ldo21>;
		huawei,ldo-names = "dvdd", "iovdd";

		gpios = <&gpio1 4 0 &gpio0 7 0 &gpio28 6 0>;
		huawei,gpio-ctrl-types = "reset", "reset2", "suspend";

		status = "ok";
	};

	&huawei_imx380hybrid {
		compatible = "huawei,sensor";
		huawei,sensor_name = "IMX380IMX351HYBRID";
		huawei,sensor_index = <0>;
		huawei,is_fpga = <0>;
		huawei,pd_valid = <1>;
		huawei,reset_valid = <1>;
		huawei,vcmpd_valid = <0>;
		huawei,csi_index = <0 2>;
		huawei,i2c_index = <0 2>;
		/*cdphy-csi2*/
		huawei,phyinfo_valid = <2>;
		huawei,is_master_sensor = <1 1>;
		huawei,phy_id = <0 2>;
		huawei,phy_mode = <0 0>;
		huawei,phy_freq_mode = <0 0>;
		huawei,phy_freq = <80000000 80000000>;
		huawei,phy_work_mode = <0 0>;
		clocks = <&clk_gate_rxdphy0_cfg &clk_gate_rxdphy1_cfg
        &clk_gate_rxdphy2_cfg &clk_gate_rxdphy3_cfg &clk_gate_isp_snclk0 &clk_gate_isp_snclk2>;
		clock-names = "clk_rxdphy0_cfg", "clk_rxdphy1_cfg", "clk_rxdphy2_cfg",
        "clk_rxdphy3_cfg", "clk_isp_snclk0", "clk_isp_snclk2";
		huawei,mclk = <19200000>;
		huawei,phyclk = <80000000>;
		phy-clock-num = <4>;
		dvdd-supply = <&ldo32>;
		iovdd-supply = <&ldo21>;
		huawei,ldo-names = "dvdd", "iovdd";

		gpios = <&gpio1 4 0 &gpio0 7 0 &gpio28 6 0>;
		huawei,gpio-ctrl-types = "reset", "reset2", "suspend";
		module_type = <0>;/*bit0=enable ,other bits=type*/
		reset_type = <3>;

		huawei,cam-power-seq-type = "sensor_suspend", "sensor_pmic",
        "sensor_pmic", "sensor_pmic", "sensor_pmic", "sensor_pmic",
		"sensor_dvdd", "sensor_iovdd", "sensor_mclk",
		"sensor_mclk", "sensor_rst",
		"sensor_rst2";
		huawei,cam-power-seq-val = <0xFF 6 0 1 4 5 0xFF 0xFF 0xFF 0xFF 0xFF 0xFF>;
		huawei,cam-power-seq-cfg-val = <0 2850000 2800000 2800000 1800000
        1100000 1140000 1800000 0 0 0 0>;
		huawei,cam-power-seq-sensor-index = <0xFF 0xFF 0xFF 0xFF 0xFF 0xFF 0xFF 0xFF 0 2 0xFF 0xFF>;
		huawei,cam-power-seq-delay = <0 0 0 0 0 0 0 1 1 1 1 1>;

		huawei,cam-power-down-seq-type =
		"sensor_rst2","sensor_rst","sensor_mclk","sensor_mclk","sensor_iovdd",
        "sensor_dvdd","sensor_pmic","sensor_pmic","sensor_pmic","sensor_pmic","sensor_pmic",
        "sensor_suspend";
		huawei,cam-power-down-seq-val = <0xFF 0xFF 0xFF 0xFF 0xFF
        0xFF 5 4 1 0 6 0xFF>;
		huawei,cam-power-down-seq-cfg-val = <0 0 0 0 1800000 1140000 1100000 1800000
        2800000 2800000 2850000 0>;
		huawei,cam-power-down-seq-sensor-index = <0xFF 0xFF 2 0 0xFF 0xFF 0xFF 0xFF 0xFF 0xFF 0xFF 0xFF>;
		huawei,cam-power-down-seq-delay = <1 1 1 1 1 0 0 0 0 0 0 0>;

		status = "ok";
	};

    &huawei_ov8856 {
        compatible = "huawei,sensor";
        huawei,sensor_name = "OV8856";
        huawei,is_fpga = <0>;
		huawei,pd_valid = <1>;
		huawei,sensor_index = <4>;
		huawei,csi_index = <1>;
		huawei,i2c_index = <1>;
		huawei,reset_valid = <1>;
        //cdphy-csi2
        huawei,phyinfo_valid = <1>;
        huawei,is_master_sensor = <1>;
        huawei,phy_id = <3>;
        huawei,phy_mode = <0>;
        huawei,phy_freq_mode = <0>;
        huawei,phy_freq = <80000000>;
        huawei,phy_work_mode = <0>;
		clock-names = "clk_isp_snclk2", "clk_rxdphy0_cfg", "clk_rxdphy1_cfg", "clk_rxdphy2_cfg", "clk_rxdphy3_cfg";
		clocks = <&clk_gate_isp_snclk2 &clk_gate_rxdphy0_cfg &clk_gate_rxdphy1_cfg &clk_gate_rxdphy2_cfg &clk_gate_rxdphy3_cfg>;
		huawei,mclk = <19200000>;
		huawei,rxdphyclk = <80000000>;
		huawei,vcmpd_valid = <0>;
		iovdd-supply = <&ldo21>;
		huawei,ldo-names = "iovdd";

		gpios = <&gpio28 4 0 &gpio24 4 0>;
		huawei,gpio-ctrl-types = "reset", "dvdd0-en";

		/*AFVDD buck2 2.85v| OIS LDO4 2.8V| AVDD LDO3 2.8V | DVDD	GPIO196 |
		 * IOVDD LDO20*/
		huawei,cam-power-seq-type = "sensor_pmic", "sensor_pmic", "sensor_pmic", "sensor_dvdd0_en",
		"sensor_iovdd", "sensor_mclk", "sensor_rst";
		huawei,cam-power-seq-cfg-val = <2850000 2800000 2800000	0 1800000 0	0>;
		huawei,cam-power-seq-val = <6 3 2 0xFF 0xFF 0xFF 0xFF>;
		huawei,cam-power-seq-sensor-index = <0xFF 0xFF 0xFF 0xFF 0xFF 2 0xFF>;
		huawei,cam-power-seq-delay = <0 0 0 0 0 1 1>;

		huawei,cam-power-down-seq-type ="sensor_rst", "sensor_mclk",
		"sensor_iovdd", "sensor_dvdd0_en", "sensor_pmic", "sensor_pmic",
		"sensor_pmic";
		huawei,cam-power-down-seq-cfg-val = <0 0 1800000 0 2800000 2800000 2850000>;
		huawei,cam-power-down-seq-val = <0xFF 0xFF 0xFF 0xFF 2 3 6>;
		huawei,cam-power-down-seq-sensor-index = <0xFF 2 0xFF 0xFF 0xFF 0xFF 0xFF>;
		huawei,cam-power-down-seq-delay = <1 1 0 0 0 0 0>;

		status = "ok";

    };

	&huawei_imx600hybrid {
		compatible = "huawei,sensor";
		huawei,sensor_name = "IMX600HYBRID";
		huawei,sensor_index = <0>;
		huawei,is_fpga = <0>;
		huawei,pd_valid = <1>;
		huawei,reset_valid = <1>;
		huawei,vcmpd_valid = <0>;
		huawei,csi_index = <0 2>;
		huawei,i2c_index = <0 2>;
        /*cdphy-csi2*/
        huawei,phyinfo_valid = <2>;
        huawei,is_master_sensor = <1 1>;
        huawei,phy_id = <0 2>;
        huawei,phy_mode = <1 0>;
        huawei,phy_freq_mode = <1 0>;
        huawei,phy_freq = <80000000 80000000>;
        huawei,phy_work_mode = <0 0>;
		/*
		phy clk define before snclk & the num of phy clk is equal to phy-clock-num
		*/
		clocks = <&clk_gate_rxdphy0_cfg &clk_gate_rxdphy1_cfg &clk_gate_rxdphy2_cfg &clk_gate_rxdphy3_cfg &clk_gate_isp_snclk0 &clk_gate_isp_snclk2>;
		clock-names = "clk_rxdphy0_cfg", "clk_rxdphy1_cfg", "clk_rxdphy2_cfg", "clk_rxdphy3_cfg", "clk_isp_snclk0", "clk_isp_snclk2";
		huawei,mclk = <19200000>;
		huawei,phyclk = <80000000>;
		phy-clock-num = <4>;
		dvdd-supply = <&ldo32>;
		iovdd-supply = <&ldo21>;
		huawei,ldo-names = "dvdd", "iovdd";

		gpios = <&gpio1 4 0 &gpio0 7 0>;
		huawei,gpio-ctrl-types = "reset", "reset2";

		huawei,cam-power-seq-type = "sensor_pmic", "sensor_pmic", "sensor_pmic",
		"sensor_pmic", "sensor_pmic",
		"sensor_dvdd", "sensor_iovdd",
		"sensor_mclk", "sensor_mclk",
		"sensor_rst", "sensor_rst2";
		huawei,cam-power-seq-cfg-val = <2850000 2800000 2800000 1800000 1100000 1140000 1800000 0 0 0 0>;
		huawei,cam-power-seq-val = <6 0 1 4 5 0xFF 0xFF 0xFF 0xFF 0xFF 0xFF>;
		huawei,cam-power-seq-sensor-index = <0xFF 0xFF 0xFF 0xFF 0xFF 0xFF 0xFF 0 2 0xFF 0xFF>;
		huawei,cam-power-seq-delay = <0 0 0 0 0 0 0 1 1 1 1>;

		huawei,cam-power-down-seq-type ="sensor_rst2", "sensor_rst", "sensor_mclk",
		"sensor_mclk", "sensor_iovdd",
		"sensor_dvdd", "sensor_pmic",
		"sensor_pmic", "sensor_pmic",
		"sensor_pmic", "sensor_pmic";
		huawei,cam-power-down-seq-cfg-val = <0 0 0 0 1800000 1140000 1100000 1800000 2800000 2800000 2850000>;
		huawei,cam-power-down-seq-val = <0xFF 0xFF 0xFF 0xFF 0xFF 0xFF 5 4 1 0 6>;
		huawei,cam-power-down-seq-sensor-index = <0xFF 0xFF 2 0 0xFF 0xFF 0xFF 0xFF 0xFF 0xFF 0xFF>;
		huawei,cam-power-down-seq-delay = <1 1 1 1 0 0 0 0 0 0 0>;

		status = "ok";
	};

	&huawei_imx355 {
		compatible = "huawei,sensor";
		huawei,sensor_name = "IMX355";
		huawei,is_fpga = <0>;
		huawei,pd_valid = <1>;
		huawei,sensor_index = <4>;
		huawei,csi_index = <1>;
		huawei,i2c_index = <2>;
		huawei,reset_valid = <1>;
        /*cdphy-csi2*/
        huawei,phyinfo_valid = <1>;
        huawei,is_master_sensor = <1>;
        huawei,phy_id = <3>;
        huawei,phy_mode = <0>;
        huawei,phy_freq_mode = <0>;
        huawei,phy_freq = <80000000>;
        huawei,phy_work_mode = <0>;
		clock-names = "clk_rxdphy0_cfg", "clk_rxdphy1_cfg", "clk_rxdphy2_cfg", "clk_rxdphy3_cfg", "clk_isp_snclk2";
		clocks = <&clk_gate_rxdphy0_cfg &clk_gate_rxdphy1_cfg &clk_gate_rxdphy2_cfg &clk_gate_rxdphy3_cfg &clk_gate_isp_snclk2>;
		huawei,mclk = <19200000>;
		huawei,rxdphyclk = <80000000>;
		huawei,vcmpd_valid = <0>;
		iovdd-supply = <&ldo21>;
		huawei,ldo-names = "iovdd";

		gpios = <&gpio28 4 0 &gpio24 4 0>;
		huawei,gpio-ctrl-types = "reset", "dvdd0-en";

		/*AFVDD buck2 2.85v| OIS LDO4 2.8V| AVDD LDO3 2.8V | DVDD	GPIO196 |
		 * IOVDD LDO20*/
		huawei,cam-power-seq-type = "sensor_pmic", "sensor_pmic", "sensor_pmic", "sensor_dvdd0_en",
		"sensor_iovdd", "sensor_mclk", "sensor_rst";
		huawei,cam-power-seq-cfg-val = <2850000 2800000 2800000	0 1800000 0	0>;
		huawei,cam-power-seq-val = <6 3 2 0xFF 0xFF 0xFF 0xFF>;
		huawei,cam-power-seq-sensor-index = <0xFF 0xFF 0xFF 0xFF 0xFF 2 0xFF>;
		huawei,cam-power-seq-delay = <0 0 0 0 0 1 1>;

		huawei,cam-power-down-seq-type ="sensor_rst", "sensor_mclk",
		"sensor_iovdd", "sensor_dvdd0_en", "sensor_pmic", "sensor_pmic",
		"sensor_pmic";
		huawei,cam-power-down-seq-cfg-val = <0 0 1800000 0 2800000 2800000 2850000>;
		huawei,cam-power-down-seq-val = <0xFF 0xFF 0xFF 0xFF 2 3 6>;
		huawei,cam-power-down-seq-sensor-index = <0xFF 2 0xFF 0xFF 0xFF 0xFF 0xFF>;
		huawei,cam-power-down-seq-delay = <1 1 0 0 0 0 0>;

		status = "ok";
	};

	&huawei_ov08a10 {
		compatible = "huawei,sensor";
		huawei,sensor_name = "OV08A10";
		huawei,is_fpga = <0>;
		huawei,pd_valid = <1>;
		huawei,sensor_index = <4>;
		huawei,csi_index = <1>;
		huawei,i2c_index = <2>;
		huawei,reset_valid = <1>;
        /*cdphy-csi2*/
        huawei,phyinfo_valid = <1>;
        huawei,is_master_sensor = <1>;
        huawei,phy_id = <3>;
        huawei,phy_mode = <0>;
        huawei,phy_freq_mode = <0>;
        huawei,phy_freq = <80000000>;
        huawei,phy_work_mode = <0>;
		clock-names = "clk_isp_snclk2", "clk_rxdphy0_cfg", "clk_rxdphy1_cfg", "clk_rxdphy2_cfg", "clk_rxdphy3_cfg";
		clocks = <&clk_gate_isp_snclk2 &clk_gate_rxdphy0_cfg &clk_gate_rxdphy1_cfg &clk_gate_rxdphy2_cfg &clk_gate_rxdphy3_cfg>;
		huawei,mclk = <19200000>;
		huawei,rxdphyclk = <80000000>;
		huawei,vcmpd_valid = <0>;
		iovdd-supply = <&ldo21>;
		huawei,ldo-names = "iovdd";

		gpios = <&gpio28 4 0 &gpio24 4 0>;
		huawei,gpio-ctrl-types = "reset", "dvdd0-en";

		/*AFVDD buck2 2.85v| OIS LDO4 2.8V| AVDD LDO3 2.8V | DVDD	GPIO196 |
		 * IOVDD LDO20*/
		huawei,cam-power-seq-type = "sensor_pmic", "sensor_pmic", "sensor_pmic", "sensor_dvdd0_en",
		"sensor_iovdd", "sensor_mclk", "sensor_rst";
		huawei,cam-power-seq-cfg-val = <2850000 2800000 2800000	0 1800000 0	0>;
		huawei,cam-power-seq-val = <6 3 2 0xFF 0xFF 0xFF 0xFF>;
		huawei,cam-power-seq-sensor-index = <0xFF 0xFF 0xFF 0xFF 0xFF 2 0xFF>;
		huawei,cam-power-seq-delay = <0 0 0 0 0 1 1>;

		huawei,cam-power-down-seq-type ="sensor_rst", "sensor_mclk",
		"sensor_iovdd", "sensor_dvdd0_en", "sensor_pmic", "sensor_pmic",
		"sensor_pmic";
		huawei,cam-power-down-seq-cfg-val = <0 0 1800000 0 2800000 2800000 2850000>;
		huawei,cam-power-down-seq-val = <0xFF 0xFF 0xFF 0xFF 2 3 6>;
		huawei,cam-power-down-seq-sensor-index = <0xFF 2 0xFF 0xFF 0xFF 0xFF 0xFF>;
		huawei,cam-power-down-seq-delay = <1 1 0 0 0 0 0>;

		status = "ok";
	};

	&huawei_ov8865 {
		compatible = "huawei,ov8865";
		huawei,sensor_name = "OV8865";
		huawei,is_fpga = <0>;
		huawei,pd_valid = <1>;
		huawei,sensor_index = <1>;
		huawei,csi_index = <0>;
		huawei,i2c_index = <1>;
		huawei,reset_valid = <1>;
		huawei,vcmpd_valid = <0>;
        /*cdphy-csi2*/
        huawei,phyinfo_valid = <1>;
        huawei,is_master_sensor = <1>;
        huawei,phy_id = <1>;
        huawei,phy_mode = <0>;
        huawei,phy_freq_mode = <0>;
        huawei,phy_freq = <80000000>;
        huawei,phy_work_mode = <0>;
		/*
		phy clk define before snclk & the num of phy clk is equal to phy-clock-num
		*/
		clocks = <&clk_gate_rxdphy0_cfg &clk_gate_rxdphy1_cfg &clk_gate_rxdphy2_cfg &clk_gate_rxdphy3_cfg &clk_gate_isp_snclk1>;
		clock-names = "clk_rxdphy0_cfg", "clk_rxdphy1_cfg", "clk_rxdphy2_cfg", "clk_rxdphy3_cfg", "clk_isp_snclk1";
		huawei,mclk = <24000000>;
		huawei,phyclk = <80000000>;
		phy-clock-num = <4>;

		dvdd-supply = <&ldo32>;
		iovdd-supply = <&ldo21>;
		huawei,ldo-names = "dvdd", "iovdd";

		gpios = <&gpio28 6 0 &gpio1 4 0 &gpio0 7 0 &gpio24 4 0>;
		huawei,gpio-ctrl-types = "reset", "suspend", "suspend2", "ldo_en";
		status = "ok";
	};

	&huawei_imx319 {
		compatible = "huawei,imx319";
		huawei,sensor_name = "IMX319";
		huawei,is_fpga = <0>;
		huawei,pd_valid = <1>;
		huawei,sensor_index = <1>;
		huawei,csi_index = <0>;
		huawei,i2c_index = <1>;
		huawei,reset_valid = <1>;
		huawei,vcmpd_valid = <0>;
        /*cdphy-csi2*/
        huawei,phyinfo_valid = <1>;
        huawei,is_master_sensor = <1>;
        huawei,phy_id = <1>;
        huawei,phy_mode = <0>;
        huawei,phy_freq_mode = <0>;
        huawei,phy_freq = <80000000>;
        huawei,phy_work_mode = <0>;
		/*
		phy clk define before snclk & the num of phy clk is equal to phy-clock-num
		*/
		clocks = <&clk_gate_rxdphy0_cfg &clk_gate_rxdphy1_cfg &clk_gate_rxdphy2_cfg &clk_gate_rxdphy3_cfg &clk_gate_isp_snclk1>;
		clock-names = "clk_rxdphy0_cfg", "clk_rxdphy1_cfg", "clk_rxdphy2_cfg", "clk_rxdphy3_cfg", "clk_isp_snclk1";
		huawei,mclk = <24000000>;
		huawei,phyclk = <80000000>;
		phy-clock-num = <4>;

		dvdd-supply = <&ldo32>;
		iovdd-supply = <&ldo21>;
		huawei,ldo-names = "dvdd", "iovdd";

		gpios = <&gpio28 6 0 &gpio1 4 0 &gpio0 7 0 &gpio24 4 0>;
		huawei,gpio-ctrl-types = "reset", "suspend", "suspend2", "ldo_en";
		status = "ok";
	};

	&huawei_imx576 {
		compatible = "huawei,sensor";
		huawei,sensor_name = "IMX576";
		huawei,is_fpga = <0>;
		huawei,pd_valid = <1>;
		huawei,sensor_index = <1>;
		huawei,csi_index = <0>;
		huawei,i2c_index = <1>;
		huawei,reset_valid = <1>;
		huawei,vcmpd_valid = <0>;
        /*cdphy-csi2*/
        huawei,phyinfo_valid = <1>;
        huawei,is_master_sensor = <1>;
        huawei,phy_id = <1>;
        huawei,phy_mode = <0>;
        huawei,phy_freq_mode = <0>;
        huawei,phy_freq = <80000000>;
        huawei,phy_work_mode = <0>;
		/*
		phy clk define before snclk & the num of phy clk is equal to phy-clock-num
		*/
		clocks = <&clk_gate_rxdphy0_cfg &clk_gate_rxdphy1_cfg &clk_gate_rxdphy2_cfg &clk_gate_rxdphy3_cfg &clk_gate_isp_snclk1>;
		clock-names = "clk_rxdphy0_cfg", "clk_rxdphy1_cfg", "clk_rxdphy2_cfg", "clk_rxdphy3_cfg", "clk_isp_snclk1";
		huawei,mclk = <19200000>;
		huawei,phyclk = <80000000>;
		phy-clock-num = <4>;

		dvdd-supply = <&ldo32>;
		iovdd-supply = <&ldo21>;
		huawei,ldo-names = "dvdd", "iovdd";

		gpios = <&gpio28 6 0 &gpio24 4 0>;
		huawei,gpio-ctrl-types = "reset", "ldo_en";

		huawei,cam-power-seq-type = "sensor_iovdd", "sensor_pmic", "sensor_dvdd",
		"sensor_mclk", "sensor_rst";
		huawei,cam-power-seq-cfg-val = <1800000 2800000 1140000 0 0>;
		huawei,cam-power-seq-sensor-index = <0xFF 0xFF 0xFF 0xFF 0xFF>;
		huawei,cam-power-seq-delay = <0 0 0 1 1>;

		huawei,cam-power-down-seq-type ="sensor_rst", "sensor_mclk", "sensor_dvdd",
		"sensor_pmic", "sensor_iovdd";
		huawei,cam-power-down-seq-cfg-val = <0 0 1140000 2800000 1800000>;
		huawei,cam-power-down-seq-sensor-index = <0xFF 0xFF 0xFF 0xFF 0xFF>;
		huawei,cam-power-down-seq-delay = <1 1 0 0 0>;

		status = "ok";
	};

	&bcm_wifi {
		ic_type = "bcm4359";
		compatible = "hisilicon,bcm_wifi";
		wifi_fw_test_name = "/vendor/firmware/fw_bcm4359_nonsig_384.bin";
		wifi_fw_ap_name = "/vendor/firmware/fw_bcm4359_apsta_hw_384.bin";
		wifi_fw_name = "/vendor/firmware/fw_bcm4359_hw_384.bin";
		wifi_nvram_name = "/vendor/firmware/nvram4359_hw_alps384_v1.txt";
		clocks = <&clk_pmu32kb>;
		clock-names = "apb_pclk";
		wlan-on,gpio-enable= <&gpio25 0 0>;
		wlan-irq,gpio-irq = <&gpio29 5 0>;
		wlan_wake,gpio_wake = <&gpio32 7 0>;
		wifi_supply_type = <0>;
		status = "ok";
	};

	/*nfc*/
	&nfc_exist {
		nfc_exist_flag = "1";
		status = "ok";
		hisee_exist_flag = "1";
	};

